# AM335x register map
Vendor: Texas Instruments; Series: Sitara AM335x; File version: 1.1
CPU: Cortex-A8 r0p0, little endian
Registers are 32-bit, read-write, reset 0x0 unless marked. A register's access mark holds for its fields unless they carry their own. Offsets are from the block's base; [hi:lo] are bit positions; 'fields as' and 'values as' point back to an identical list.

## CM_WKUP — Clock Module - Wakeup
Base 0x44E00400
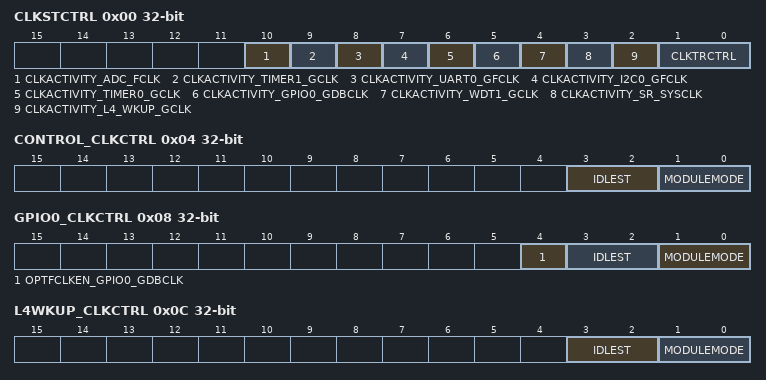
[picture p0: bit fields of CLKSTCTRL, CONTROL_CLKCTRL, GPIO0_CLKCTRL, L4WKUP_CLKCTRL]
0x00 CLKSTCTRL
  [10] CLKACTIVITY_ADC_FCLK — bit: 14 (R)state of the clock in domain [see e_PRCM_CLK_DOMAIN_ST]
  [9] CLKACTIVITY_TIMER1_GCLK ro — bit: 13 Reserved
  [8] CLKACTIVITY_UART0_GFCLK — bit: 12 (R)state of the clock in domain [see e_PRCM_CLK_DOMAIN_ST]
  [7] CLKACTIVITY_I2C0_GFCLK — bit: 11 (R)state of the clock in domain [see e_PRCM_CLK_DOMAIN_ST]
  [6] CLKACTIVITY_TIMER0_GCLK — bit: 10 (R)state of the clock in domain [see e_PRCM_CLK_DOMAIN_ST]
  [5] CLKACTIVITY_GPIO0_GDBCLK — bit: 8 (R)state of the clock in domain [see e_PRCM_CLK_DOMAIN_ST]
  [4] CLKACTIVITY_WDT1_GCLK — bit: 4 (R)state of the clock in domain [see e_PRCM_CLK_DOMAIN_ST]
  [3] CLKACTIVITY_SR_SYSCLK — bit: 3 (R)state of the clock in domain [see e_PRCM_CLK_DOMAIN_ST]
  [2] CLKACTIVITY_L4_WKUP_GCLK — bit: 2 (R)state of the clock in domain [see e_PRCM_CLK_DOMAIN_ST]
  [1:0] CLKTRCTRL — bit: 0,1 (RW)Clock state transition [see e_PRCM_CLKTRCTRL]
0x04 CONTROL_CLKCTRL — CM_CLKCTRL Register
  [3:2] IDLEST — bit: 16,17 (R)Module idle status.[see e_PRCM_IDLEST]
  [1:0] MODULEMODE — bit: 0,1 (RW)Control the way mandatory clocks are managed.[see e_PRCM_MODULEMODE]
0x08 GPIO0_CLKCTRL
  [4] OPTFCLKEN_GPIO0_GDBCLK — bit: 18 (RW)Optional functional clock control.[0x0 = disabled; 0x1= enabled]
  [3:2] IDLEST — bit: 16,17 (R)Module idle status.[see e_PRCM_IDLEST]
  [1:0] MODULEMODE — bit: 0,1 (RW)Control the way mandatory clocks are managed.[see e_PRCM_MODULEMODE]
0x0C L4WKUP_CLKCTRL — CM_CLKCTRL Register
  fields as CONTROL_CLKCTRL
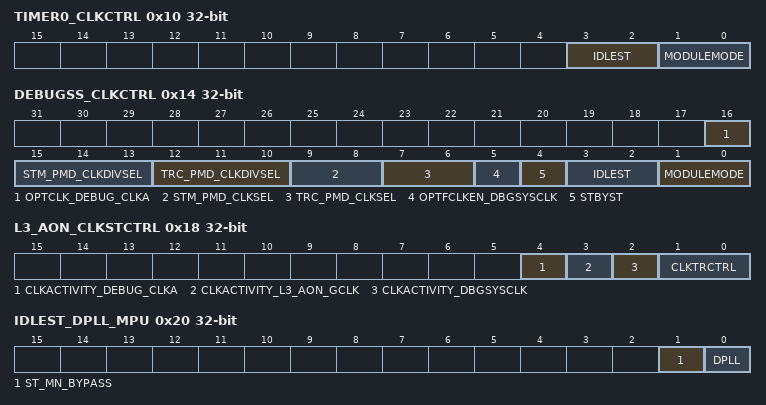
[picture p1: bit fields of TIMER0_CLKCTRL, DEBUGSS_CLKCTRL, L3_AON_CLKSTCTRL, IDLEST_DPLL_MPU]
0x10 TIMER0_CLKCTRL — CM_CLKCTRL Register
  fields as CONTROL_CLKCTRL
0x14 DEBUGSS_CLKCTRL
  [16] OPTCLK_DEBUG_CLKA — bit: 30 (RW)Optional functional clock control.[0x0 = disabled.; 0x1= enabled.]
  [15:13] STM_PMD_CLKDIVSEL
  [12:10] TRC_PMD_CLKDIVSEL
  [9:8] STM_PMD_CLKSEL — bit: 22,23
  [7:6] TRC_PMD_CLKSEL — bit: 20,21
  [5] OPTFCLKEN_DBGSYSCLK — bit: 19 (RW)Optional functional clock control.[0x0 = disabled; 0x1= enabled]
  [4] STBYST — bit: 18 (R)Module standby status.[see e_PRCM_STBYST]
  [3:2] IDLEST — bit: 16,17 (R)Module idle status.[see e_PRCM_IDLEST]
  [1:0] MODULEMODE — bit: 0,1 (RW)Control the way mandatory clocks are managed.[see e_PRCM_MODULEMODE]
0x18 L3_AON_CLKSTCTRL
  [4] CLKACTIVITY_DEBUG_CLKA — bit: 4 (R)state of the Debugss CLKA clock in domain [0x0 = gated; 0x1= active]
  [3] CLKACTIVITY_L3_AON_GCLK — bit: 3 (R)state of the L3_AON clock in domain [0x0 = gated; 0x1= active]
  [2] CLKACTIVITY_DBGSYSCLK — bit: 2 (R)state of the Debugss clock in domain [0x0 = gated; 0x1= active]
  [1:0] CLKTRCTRL — bit: 0,1 (RW)Clock state transition [see e_PRCM_CLKTRCTRL]
0x1C AUTOIDLE_DPLL_MPU
  [2:0] AUTO_DPLL_MODE — This feature is not supported.
0x20 IDLEST_DPLL_MPU
  [1] ST_MN_BYPASS — bit: 8 (RW)DPLL MN_BYPASS status [0x0 = not bypass; 0x1= bypass]
  [0] DPLL — bit: 0 (RW)DPLL clock activity [0x0 = in bypass or in stop mode; 0x1= locked]
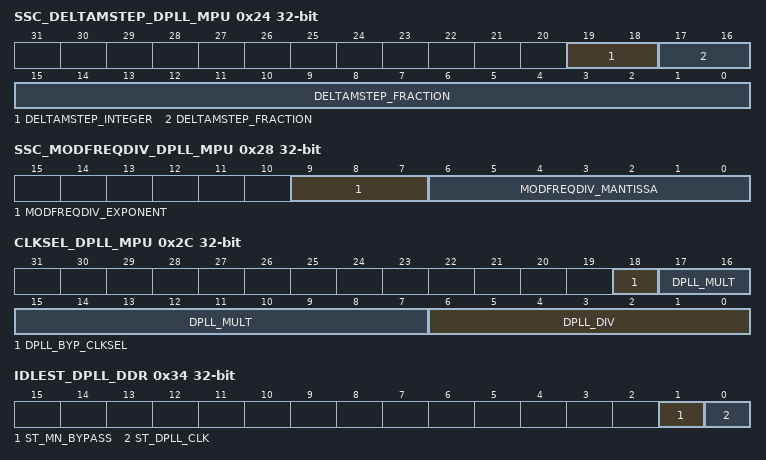
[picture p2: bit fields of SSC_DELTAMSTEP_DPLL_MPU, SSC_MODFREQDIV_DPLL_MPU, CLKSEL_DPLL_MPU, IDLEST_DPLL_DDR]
0x24 SSC_DELTAMSTEP_DPLL_MPU
  [19:18] DELTAMSTEP_INTEGER — bit: 18,19 (RW)Integer part for DeltaM coefficient
  [17:0] DELTAMSTEP_FRACTION — Fractional part for DeltaM coefficient
0x28 SSC_MODFREQDIV_DPLL_MPU
  [9:7] MODFREQDIV_EXPONENT — Set the Exponent component of MODFREQDIV factor
  [6:0] MODFREQDIV_MANTISSA — Set the Mantissa component of MODFREQDIV factor
0x2C CLKSEL_DPLL_MPU
  [18] DPLL_BYP_CLKSEL — bit: 23 [ 0x0 = Selects CLKINP Clock as BYPASS Clock; 0x1 = Selects CLKINPULOW as Bypass Clock ]
  [17:7] DPLL_MULT ro — DPLL multiplier factor (2 to 2047). [0x0 = 0 reserved; 0x1= 1 reserved]
  [6:0] DPLL_DIV — DPLL divider factor (0 to 127) (equal to input N of DPLL actual division factor is N+1).
0x30 AUTOIDLE_DPLL_DDR
  [2:0] AUTO_DPLL_MODE — AUTO_DPLL_MODE is not supported.
0x34 IDLEST_DPLL_DDR
  [1] ST_MN_BYPASS — bit: 8 DPLL MN_BYPASS status [0x0 = not in bypass; 0x1 = bypass ]
  [0] ST_DPLL_CLK — bit: 0 DPLL clock activity [0x0 = in bypass or in stop mode; 0x1 = locked ]
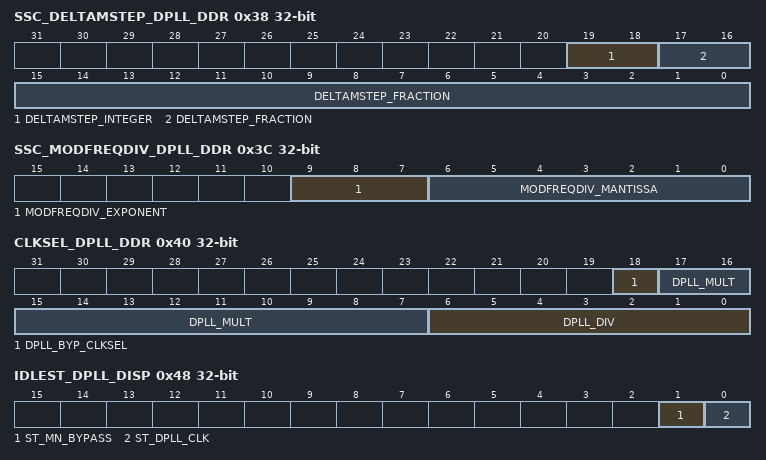
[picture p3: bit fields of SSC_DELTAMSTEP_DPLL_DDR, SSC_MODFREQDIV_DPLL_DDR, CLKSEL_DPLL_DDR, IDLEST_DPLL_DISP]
0x38 SSC_DELTAMSTEP_DPLL_DDR
  [19:18] DELTAMSTEP_INTEGER — bit: 18,19 Integer part for DeltaM coefficient
  [17:0] DELTAMSTEP_FRACTION — Fractional part for DeltaM coefficient
0x3C SSC_MODFREQDIV_DPLL_DDR
  fields as SSC_MODFREQDIV_DPLL_MPU
0x40 CLKSEL_DPLL_DDR
  fields as CLKSEL_DPLL_MPU
0x44 AUTOIDLE_DPLL_DISP
  [2:0] AUTO_DPLL_MODE — AUTO_DPLL_MODE is not supported.
0x48 IDLEST_DPLL_DISP
  fields as IDLEST_DPLL_DDR
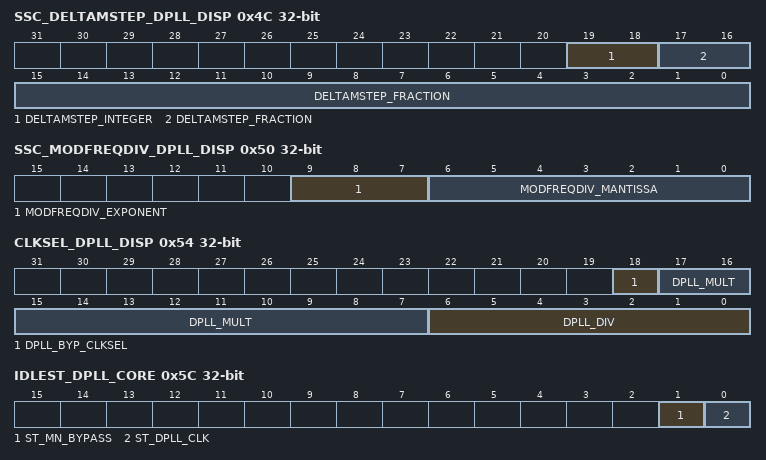
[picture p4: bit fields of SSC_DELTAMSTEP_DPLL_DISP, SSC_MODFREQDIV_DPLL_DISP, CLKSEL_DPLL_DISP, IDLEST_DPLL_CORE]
0x4C SSC_DELTAMSTEP_DPLL_DISP
  fields as SSC_DELTAMSTEP_DPLL_MPU
0x50 SSC_MODFREQDIV_DPLL_DISP
  fields as SSC_MODFREQDIV_DPLL_MPU
0x54 CLKSEL_DPLL_DISP
  [18] DPLL_BYP_CLKSEL — bit: 23 (RW)SSC_MODFREQDIV_DPLL_DISP_reg_t[ 0x0 = Selects CLKINP Clock as BYPASS Clock; 0x1 = Selects CLKINPULOW as Bypass Clock ]
  [17:7] DPLL_MULT — DPLL multiplier factor (2 to 2047). [0x0 = 0 reserved; 0x1= 1 reserved]
  [6:0] DPLL_DIV — DPLL divider factor (0 to 127) (equal to input N of DPLL actual division factor is N+1).
0x58 AUTOIDLE_DPLL_CORE
  [2:0] AUTO_DPLL_MODE — AUTO_DPLL_MODE is not supported.
0x5C IDLEST_DPLL_CORE
  fields as IDLEST_DPLL_DDR
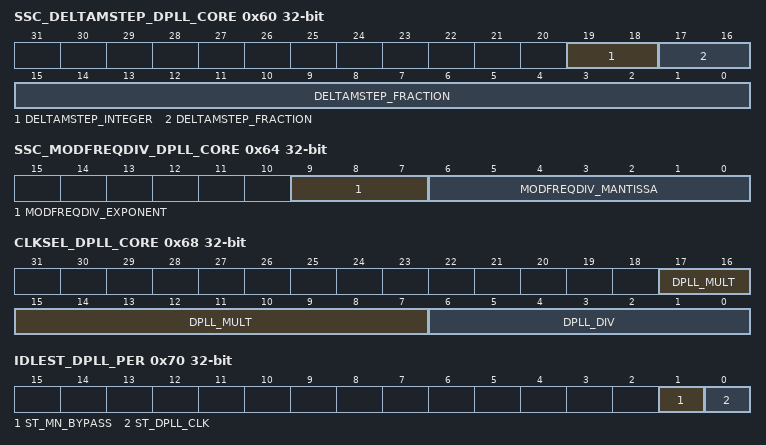
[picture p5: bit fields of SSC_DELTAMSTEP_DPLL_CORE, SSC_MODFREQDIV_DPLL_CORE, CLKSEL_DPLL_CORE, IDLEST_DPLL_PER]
0x60 SSC_DELTAMSTEP_DPLL_CORE
  fields as SSC_DELTAMSTEP_DPLL_MPU
0x64 SSC_MODFREQDIV_DPLL_CORE
  fields as SSC_MODFREQDIV_DPLL_MPU
0x68 CLKSEL_DPLL_CORE
  [17:7] DPLL_MULT — DPLL multiplier factor (2 to 2047). [0x0 = 0 reserved; 0x1= 1 reserved]
  [6:0] DPLL_DIV — DPLL divider factor (0 to 127) (equal to input N of DPLL actual division factor is N+1).
0x6C AUTOIDLE_DPLL_PER
  [2:0] AUTO_DPLL_MODE — AUTO_DPLL_MODE is not supported.
0x70 IDLEST_DPLL_PER
  fields as IDLEST_DPLL_DDR
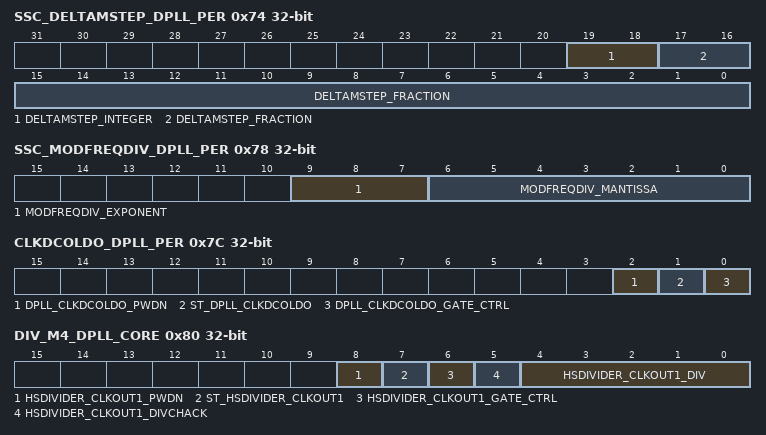
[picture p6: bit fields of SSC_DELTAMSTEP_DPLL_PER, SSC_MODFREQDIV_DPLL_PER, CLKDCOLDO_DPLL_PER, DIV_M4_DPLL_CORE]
0x74 SSC_DELTAMSTEP_DPLL_PER
  fields as SSC_DELTAMSTEP_DPLL_MPU
0x78 SSC_MODFREQDIV_DPLL_PER
  fields as SSC_MODFREQDIV_DPLL_MPU
0x7C CLKDCOLDO_DPLL_PER
  [2] DPLL_CLKDCOLDO_PWDN — bit: 12 (RW)Automatic power down for CLKDCOLDO o/p when it is gated [0x0 = keep powered;0x1 = powerdown]
  [1] ST_DPLL_CLKDCOLDO — bit: 9 (R) DPLL CLKDCOLDO status[0x0 = gated;0x1 = enabled]
  [0] DPLL_CLKDCOLDO_GATE_CTRL — bit: 8 (RW) Control gating of DPLL CLKDCOLDO [0x0 = Automatically gate;0x1 = Force this clock]
0x80 DIV_M4_DPLL_CORE
  [8] HSDIVIDER_CLKOUT1_PWDN — bit: 12 Automatic power down for HSDIVIDER M4 divider and henceCLKOUT1 output when the o/p clock is gated [0x0 = keep powered;0x1 = powerdown]
  [7] ST_HSDIVIDER_CLKOUT1 — bit: 9 (R)HSDIVIDER CLKOUT1 status [0x0 = gated;0x1 = enabled]
  [6] HSDIVIDER_CLKOUT1_GATE_CTRL — bit: 8 (RW)Control gating of HSDIVIDER CLKOUT1 [0x0 = auto gated;0x1 = force enabled]
  [5] HSDIVIDER_CLKOUT1_DIVCHACK — bit: 5 (R)indicates that the change in divider HSDIVIDER_CLKOUT1_DIV value has taken effect.
  [4:0] HSDIVIDER_CLKOUT1_DIV — DPLL post-divider factor, M4, for internal clock generation.Divide values from 1 to 31. [0x0 = reserved]
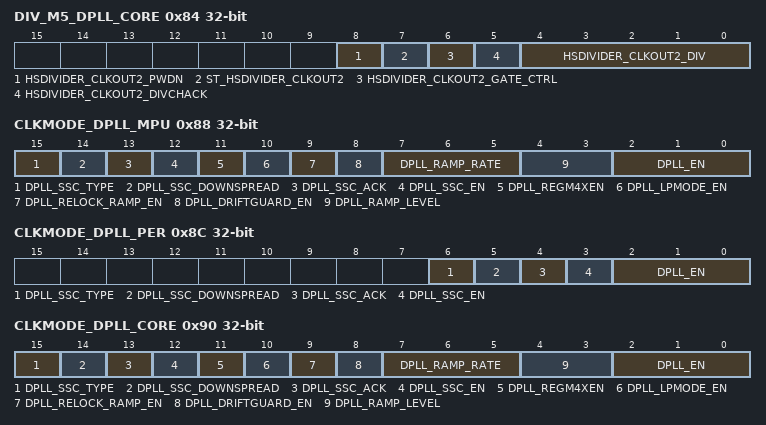
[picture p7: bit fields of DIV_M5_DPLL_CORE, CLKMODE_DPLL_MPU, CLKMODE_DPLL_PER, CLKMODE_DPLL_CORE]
0x84 DIV_M5_DPLL_CORE
  [8] HSDIVIDER_CLKOUT2_PWDN — bit: 12 Automatic power down for HSDIVIDER M5 divider and henceCLKOUT2 output when the o/p clock is gated [0x0 = keep powered;0x1 = powerdown]
  [7] ST_HSDIVIDER_CLKOUT2 — bit: 9 (R)HSDIVIDER CLKOUT2 status [0x0 = gated;0x1 = enabled]
  [6] HSDIVIDER_CLKOUT2_GATE_CTRL — bit: 8 (RW)Control gating of HSDIVIDER CLKOUT2 [0x0 = auto gated;0x1 = force enabled]
  [5] HSDIVIDER_CLKOUT2_DIVCHACK — bit: 5 (R)indicates that the change in divider HSDIVIDER_CLKOUT2_DIV value has taken effect.
  [4:0] HSDIVIDER_CLKOUT2_DIV — DPLL post-divider factor, M5, for internal clock generation.Divide values from 1 to 31. [0x0 = reserved]
0x88 CLKMODE_DPLL_MPU
  [15] DPLL_SSC_TYPE ro — bit: 15 (RW) Select Triangular Spread Spectrum clocking. [0x0 = is selected; 0x1 = Reserved]
  [14] DPLL_SSC_DOWNSPREAD — bit: 14 (RW) Control if only low frequency spread is required [0x0 = spread on both sides of the programmed frequency; 0x1 = spread only on the lower side of the programmed frequency]
  [13] DPLL_SSC_ACK — bit: 13 (R) Acknowledgement from the DPLL regarding start and stop of Spread Spectrum Clocking feature [0x0 = SSC turned off; 0x1 = SSC turned on]
  [12] DPLL_SSC_EN — bit: 12 (RW) Enable or disable Spread Spectrum Clocking [0x0 = SSC disabled; 0x1 = SSC enabled]
  [11] DPLL_REGM4XEN — bit: 11 (Retrun 0) Enable the REGM4XEN mode of the DPLL.
  [10] DPLL_LPMODE_EN — bit: 10 (RW) Set the DPLL in Low Power mode.
  [9] DPLL_RELOCK_RAMP_EN — bit: 9 (RW) If enabled, the clock ramping feature is used applied during the lock process, as well as the relock process
  [8] DPLL_DRIFTGUARD_EN — bit: 8 (RW) This bit allows to enable or disable the automatic recalibration feature of the DPLL. DRIFTGUARD feature [0x0 = disabled; 0x1 = enabled]
  [7:5] DPLL_RAMP_RATE — selects the time in terms of DPLL REFCLKs spent at each stage of the clock ramping process. see e_DPLL_RAMP_RATE
  [4:3] DPLL_RAMP_LEVEL — bit: 3,4 (RW) clock frequency ramping feature [variants:0x0;0x1;0x2;0x3]see datasheet and e_DPLL_RAMP_LEVEL
  [2:0] DPLL_EN — DPLL control.[see e_MPU_DPLL_EN]
0x8C CLKMODE_DPLL_PER
  [6] DPLL_SSC_TYPE ro — bit: 15 (RW) Select Triangular Spread Spectrum clocking. [0x0 = is selected; 0x1 = Reserved]
  [5] DPLL_SSC_DOWNSPREAD — bit: 14 (RW) Control if only low frequency spread is required [0x0 = spread on both sides of the programmed frequency; 0x1 = spread only on the lower side of the programmed frequency]
  [4] DPLL_SSC_ACK — bit: 13 (R) Acknowledgement from the DPLL regarding start and stop of Spread Spectrum Clocking feature [0x0 = SSC turned off; 0x1 = SSC turned on]
  [3] DPLL_SSC_EN — bit: 12 (RW) Enable or disable Spread Spectrum Clocking [0x0 = SSC disabled; 0x1 = SSC enabled]
  [2:0] DPLL_EN — DPLL control.[see e_PER_DPLL_EN]
0x90 CLKMODE_DPLL_CORE
  [15] DPLL_SSC_TYPE ro — bit: 15 (RW) Select Triangular Spread Spectrum clocking. [0x0 = is selected; 0x1 = Reserved]
  [14] DPLL_SSC_DOWNSPREAD — bit: 14 (RW) Control if only low frequency spread is required [0x0 = spread on both sides of the programmed frequency; 0x1 = spread only on the lower side of the programmed frequency]
  [13] DPLL_SSC_ACK — bit: 13 (R) Acknowledgement from the DPLL regarding start and stop of Spread Spectrum Clocking feature [0x0 = SSC turned off; 0x1 = SSC turned on]
  [12] DPLL_SSC_EN — bit: 12 (RW) Enable or disable Spread Spectrum Clocking [0x0 = SSC disabled; 0x1 = SSC enabled]
  [11] DPLL_REGM4XEN — bit: 11 (Retrun 0) Enable the REGM4XEN mode of the DPLL.
  [10] DPLL_LPMODE_EN — bit: 10 (RW) Set the DPLL in Low Power mode.
  [9] DPLL_RELOCK_RAMP_EN — bit: 9 (RW) If enabled, the clock ramping feature is used applied during the lock process, as well as the relock process
  [8] DPLL_DRIFTGUARD_EN — bit: 8 (RW) This bit allows to enable or disable the automatic recalibration feature of the DPLL. DRIFTGUARD feature [0x0 = disabled; 0x1 = enabled]
  [7:5] DPLL_RAMP_RATE — selects the time in terms of DPLL REFCLKs spent at each stage of the clock ramping process. see e_DPLL_RAMP_RATE
  [4:3] DPLL_RAMP_LEVEL — bit: 3,4 (RW) clock frequency ramping feature [variants:0x0;0x1;0x2;0x3]see datasheet and e_DPLL_RAMP_LEVEL
  [2:0] DPLL_EN — DPLL control.[see e_DPLL_EN]
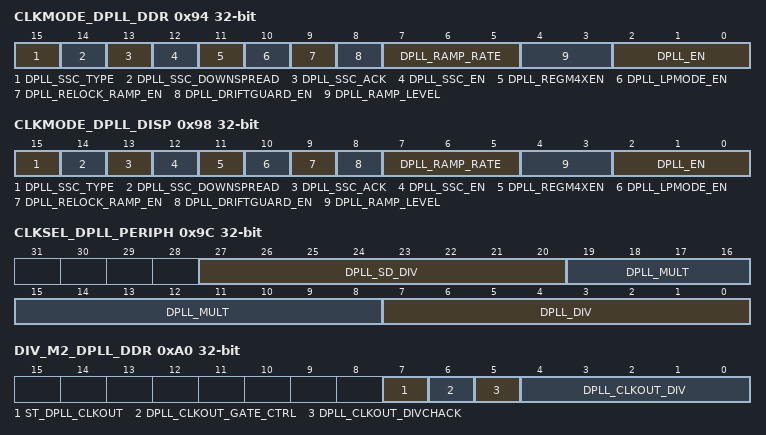
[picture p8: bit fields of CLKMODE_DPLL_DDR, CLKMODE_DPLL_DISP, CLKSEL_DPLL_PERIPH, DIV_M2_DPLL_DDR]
0x94 CLKMODE_DPLL_DDR
  fields as CLKMODE_DPLL_CORE
0x98 CLKMODE_DPLL_DISP
  fields as CLKMODE_DPLL_CORE
0x9C CLKSEL_DPLL_PERIPH
  [27:20] DPLL_SD_DIV — Sigma-Delta divider select (2-255)[0x0,0x1 - reserved].
  [19:8] DPLL_MULT — DPLL multiplier factor (2 to 4095)[0x0,0x1 - reserved]..
  [7:0] DPLL_DIV — DPLL divider factor (0 to 255)
0xA0 DIV_M2_DPLL_DDR
  [7] ST_DPLL_CLKOUT — bit: 9 (R)DPLL CLKOUT status [0x0 = gated;0x1 = enabled]
  [6] DPLL_CLKOUT_GATE_CTRL — bit: 8 (RW)Control gating of DPLL CLKOUT [0x0 = auto gated;0x1 = force enabled]
  [5] DPLL_CLKOUT_DIVCHACK — bit: 5 (R)indicates that the change in divider DPLL_CLKOUT_DIV value has taken effect.
  [4:0] DPLL_CLKOUT_DIV — DPLL M2 post-divider factor (1 to 31). [0x0 = reserved]
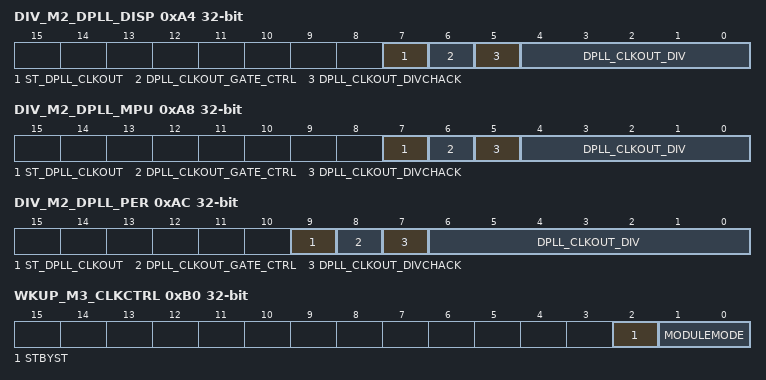
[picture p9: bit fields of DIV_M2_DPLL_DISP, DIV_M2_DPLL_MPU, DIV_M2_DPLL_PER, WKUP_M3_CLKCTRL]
0xA4 DIV_M2_DPLL_DISP
  fields as DIV_M2_DPLL_DDR
0xA8 DIV_M2_DPLL_MPU
  fields as DIV_M2_DPLL_DDR
0xAC DIV_M2_DPLL_PER
  [9] ST_DPLL_CLKOUT — bit: 9 (R)DPLL CLKOUT status [0x0 = gated;0x1 = enabled]
  [8] DPLL_CLKOUT_GATE_CTRL — bit: 8 (RW)Control gating of DPLL CLKOUT [0x0 = auto gated;0x1 = force enabled]
  [7] DPLL_CLKOUT_DIVCHACK — bit: 7 (R)indicates that the change in divider DPLL_CLKOUT_DIV value has taken effect.
  [6:0] DPLL_CLKOUT_DIV — DPLL M2 post-divider factor (1 to 31). [0x0 = reserved]
0xB0 WKUP_M3_CLKCTRL
  [2] STBYST — bit: 18 (R)Module standby status.[see e_PRCM_STBYST]
  [1:0] MODULEMODE — bit: 0,1 (RW)Control the way mandatory clocks are managed.[see e_PRCM_MODULEMODE]
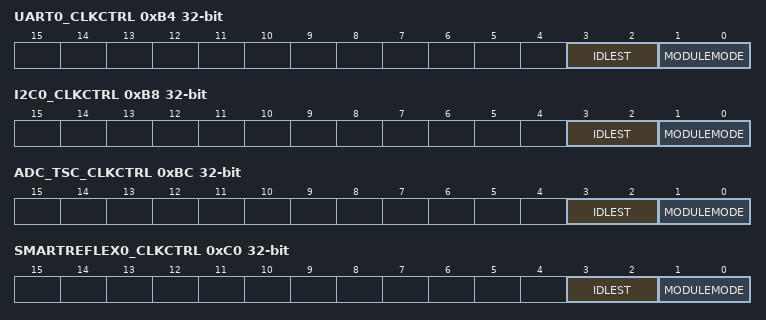
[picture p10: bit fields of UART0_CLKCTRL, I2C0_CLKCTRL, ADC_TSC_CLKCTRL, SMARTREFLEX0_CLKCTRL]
0xB4 UART0_CLKCTRL — CM_CLKCTRL Register
  fields as CONTROL_CLKCTRL
0xB8 I2C0_CLKCTRL — CM_CLKCTRL Register
  fields as CONTROL_CLKCTRL
0xBC ADC_TSC_CLKCTRL — CM_CLKCTRL Register
  fields as CONTROL_CLKCTRL
0xC0 SMARTREFLEX0_CLKCTRL — CM_CLKCTRL Register
  fields as CONTROL_CLKCTRL
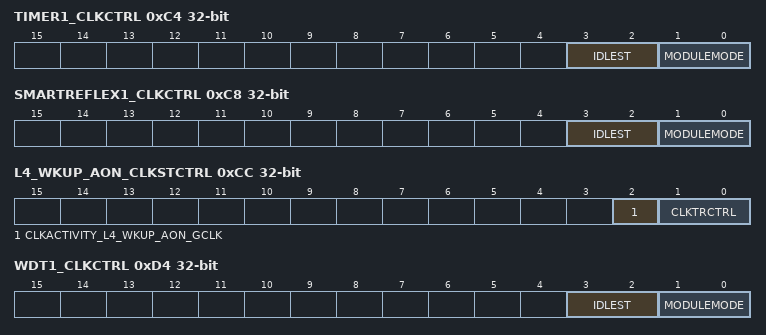
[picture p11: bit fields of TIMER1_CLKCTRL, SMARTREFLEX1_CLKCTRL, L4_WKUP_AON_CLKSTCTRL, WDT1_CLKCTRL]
0xC4 TIMER1_CLKCTRL — CM_CLKCTRL Register
  fields as CONTROL_CLKCTRL
0xC8 SMARTREFLEX1_CLKCTRL — CM_CLKCTRL Register
  fields as CONTROL_CLKCTRL
0xCC L4_WKUP_AON_CLKSTCTRL
  [2] CLKACTIVITY_L4_WKUP_AON_GCLK — bit: 2 (R)state of the clock in domain [0x0 = gated; 0x1= Act]
  [1:0] CLKTRCTRL — bit: 0,1 (RW)Clock state transition [see e_PRCM_CLKTRCTRL]
0xD4 WDT1_CLKCTRL — CM_CLKCTRL Register
  fields as CONTROL_CLKCTRL
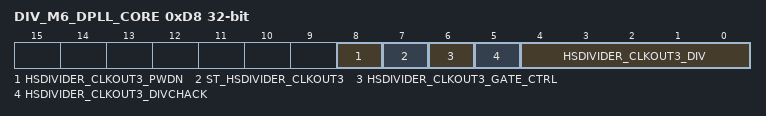
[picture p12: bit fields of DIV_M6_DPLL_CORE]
0xD8 DIV_M6_DPLL_CORE
  [8] HSDIVIDER_CLKOUT3_PWDN — bit: 12 (RW)Automatic power down for HSDIVIDER M6 divider [0x0 = Keep powered on; 0x1 = Automatically power down;]
  [7] ST_HSDIVIDER_CLKOUT3 — bit: 9 (R)HSDIVIDER CLKOUT3 status [0x0 = gated; 0x1 = enabled;]
  [6] HSDIVIDER_CLKOUT3_GATE_CTRL — bit: 8 (RW)Control gating of HSDIVIDER CLKOUT3 [0x0 = autogate; 0x1 = force enabled;]
  [5] HSDIVIDER_CLKOUT3_DIVCHACK — bit: 5 (R)indicates that the change in divider HSDIVIDER_CLKOUT3_DIV value has taken effect
  [4:0] HSDIVIDER_CLKOUT3_DIV — Control the way mandatory clocks are managed.[see e_PRCM_MODULEMODE]
